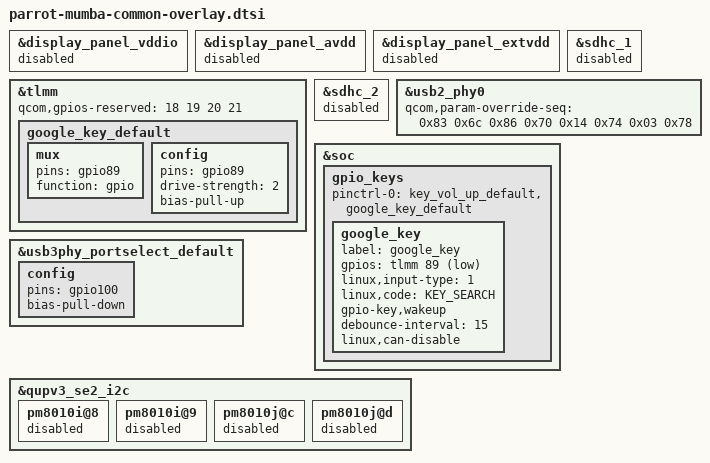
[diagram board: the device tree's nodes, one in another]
/* Copyright (c) 2021, The Linux Foundation. All rights reserved.
 *
 * This program is free software; you can redistribute it and/or modify
 * it under the terms of the GNU General Public License version 2 and
 * only version 2 as published by the Free Software Foundation.
 *
 * This program is distributed in the hope that it will be useful,
 * but WITHOUT ANY WARRANTY; without even the implied warranty of
 * MERCHANTABILITY or FITNESS FOR A PARTICULAR PURPOSE.  See the
 * GNU General Public License for more details.
 */
#include "parrot-moto-common-overlay-base.dtsi"
#include "parrot-moto-common-overlay.dtsi"
#include "parrot-portov-and-mumba-charger-overlay.dtsi"
#include "parrot-mumba-fmr-overlay.dtsi"
#include "parrot-mumba-thermal-overlay.dtsi"
#include "parrot-portov-touchscreen-overlay.dtsi"
#include "parrot-mumba-sensor-overlay.dtsi"
#include "parrot-portov-nfc-overlay.dtsi"
#include "parrot-portov-fps-overlay.dtsi"
//#include "parrot-mona-haptics-overlay.dtsi"

&display_panel_vddio {
         status = "disabled";
};

&display_panel_avdd {
         status = "disabled";
};

&display_panel_extvdd {
         status = "disabled";
};

&tlmm {
	qcom,gpios-reserved = <18 19 20 21>;
};

&sdhc_1 {
	status = "disabled";
};

&sdhc_2 {
	status = "disabled";
};

&usb2_phy0 {
	qcom,param-override-seq = <
			0x83 0x6c
			0x86 0x70
			0x14 0x74
			0x03 0x78>;
};

&tlmm {
	google_key_default: google_key_default {
		mux {
			pins = "gpio89";
			function = "gpio";
		};

		config {
			pins = "gpio89";
			drive-strength = <2>;
			bias-pull-up;
		};
	};
};

&soc {
	gpio_keys {
		pinctrl-0 = <&key_vol_up_default &google_key_default>;

		google_key {
			label = "google_key";
			gpios = <&tlmm 89 GPIO_ACTIVE_LOW>;
			linux,input-type = <1>;
			linux,code = <KEY_SEARCH>;
			gpio-key,wakeup;
			debounce-interval = <15>;
			linux,can-disable;
		};
	};
};

&usb3phy_portselect_default {
	config {
		pins = "gpio100";
		bias-pull-down;
	};
};

&qupv3_se2_i2c {
	pm8010i@8 {
		status = "disabled";
	};

	pm8010i@9{
		status = "disabled";
	};

	pm8010j@c{
		status = "disabled";
	};

	pm8010j@d{
		status = "disabled";
	};
};
